# RS14100 register map
File version: 1.0
CPU: CM4 r0p1, little endian, MPU, FPU, 4 interrupt priority bits
Registers are 32-bit, read-write, reset 0x0 unless marked. A register's access mark holds for its fields unless they carry their own. Offsets are from the block's base; [hi:lo] are bit positions.

## CCI — CCI module helps external memories and peripherals to communicate with internal AHB bus with less number of pins
Base 0x46170000
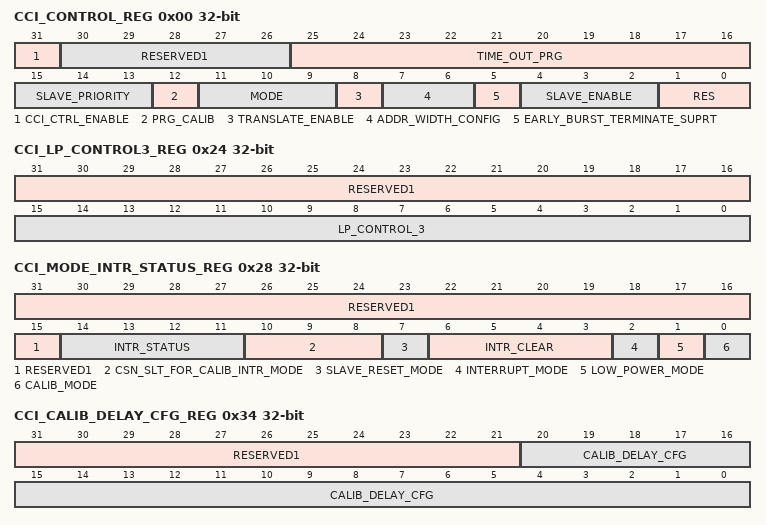
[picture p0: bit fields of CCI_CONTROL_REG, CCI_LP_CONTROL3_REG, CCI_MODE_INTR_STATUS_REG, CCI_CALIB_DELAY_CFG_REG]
0x00 CCI_CONTROL_REG — Direct Access Registers
  [31] CCI_CTRL_ENABLE — configurable time out value for slave response.
  [30:26] RESERVED1 — reser
  [25:16] TIME_OUT_PRG — configurable time out value for slave response.
  [15:13] SLAVE_PRIORITY — This bits will represents priority of the slaves
  [12] PRG_CALIB — By setting this bit, calibration turn around delay value will be configured
  [11:9] MODE — This bit represents mode of the interface
  [8] TRANSLATE_ENABLE — translation enable
  [7:6] ADDR_WIDTH_CONFIG — address width configuration of slave
  [5] EARLY_BURST_TERMINATE_SUPRT — Support for Early Burst Termination
  [4:2] SLAVE_ENABLE — Indicates Slaves enable
  [1:0] RES — reseR
0x04 CCI_LSB_A_S1_REG — Lower Address of slave 0 supported
0x08 CCI_LSB_A_S2_REG — LOWER Address of slave 0 supported
0x0C CCI_LSB_A_S3_REG — Lower Address of slave 0 supported
0x10 CCI_MSB_A_S1_REG — upper Address of slave 0 supported
0x14 CCI_MSB_A_S2_REG — UPPER Address of slave 0 supported
0x18 CCI_MSB_A_S3_REG — upper Address of slave 0 supported
0x1C CCI_LP_CONTROL1_REG — low power control - 1Configuration.It holds the lower 32 bits low power control values of the peer chip, once low power mode triggered then this bits will be transferred on to the interface
0x20 CCI_LP_CONTROL2_REG — low power control - 2 Configuration.It holds 64 to 33 bits the low power control values of the peer chip, once low power mode triggered then this bits will be transferred on to the interface
0x24 CCI_LP_CONTROL3_REG — low power control - 3 Configuration.It holds 80 to 64 bits the low power control values of the peer chip, once low power mode triggered then this bits will be transferred on to the interface
  [31:16] RESERVED1 — RESERV
  [15:0] LP_CONTROL_3 — It holds 80 to 64 bits the low power control values of the peer chip, once low power mode triggered then this bits will be transferred on to the interface
0x28 CCI_MODE_INTR_STATUS_REG — Interrupt Status
  [31:15] RESERVED1 — RESER
  [14:11] INTR_STATUS — These bits will represents the status of the interrupt in read mode
  [10:8] CSN_SLT_FOR_CALIB_INTR_MODE — CSN select value from register in calibration, and low power mode.
  [7] SLAVE_RESET_MODE — initiate the slave reset command from AMS
  [6:3] INTR_CLEAR — By setting this bits will clear the interrupt status
  [2] INTERRUPT_MODE — This bit is used to trigger the interrupt message mode
  [1] LOW_POWER_MODE — This bit is used to trigger the low power mode
  [0] CALIB_MODE — This bit is used to trigger the calibration mode
0x34 CCI_CALIB_DELAY_CFG_REG — Calibration delay Configuration
  [31:21] RESERVED1 — RESER
  [20:0] CALIB_DELAY_CFG — This register holds the turn around delays for the three ms chips
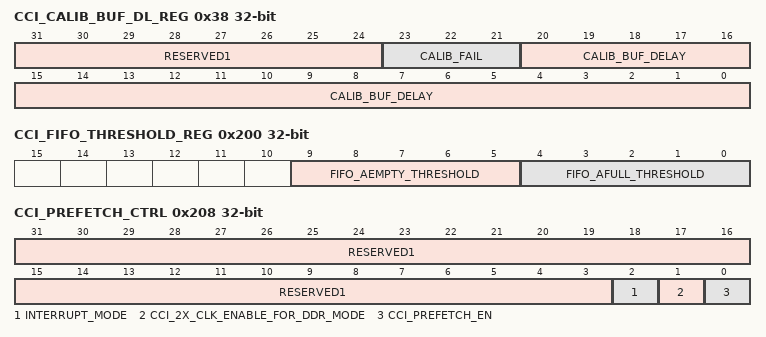
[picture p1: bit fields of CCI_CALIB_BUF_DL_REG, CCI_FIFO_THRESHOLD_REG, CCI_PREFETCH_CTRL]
0x38 CCI_CALIB_BUF_DL_REG — Calibration Maximum delay
  [31:24] RESERVED1 — RESER
  [23:21] CALIB_FAIL ro — this bits will represents the status of the calibration
  [20:0] CALIB_BUF_DELAY — This register holds the maximum tuning delays for the three ms chips
0x3C LP_CONTROL_4 — low power control
  [31:0] LP_CONTROL_4_ — It holds the lower 32 bits low power control values of the peer chip, once low power mode triggered then this bits will be transferred on to the interface
0x40 LP_CONTROL_5 — low power control
  [31:0] LP_CONTROL_5 — It holds the lower 32 bits low power control values of the peer chip, once low power mode triggered then this bits will be transferred on to the interfaces
0x200 CCI_FIFO_THRESHOLD_REG — CCI fifo threshold
  [9:5] FIFO_AEMPTY_THRESHOLD — ALMOST empty threshold
  [4:0] FIFO_AFULL_THRESHOLD — ALMOST full threshold
0x204 CCI_TRANS_ADDRESS
0x208 CCI_PREFETCH_CTRL — CCI prefetch control register
  [31:3] RESERVED1 — RESERV
  [2] INTERRUPT_MODE — This bit is used to trigger the interrupt message mode.
  [1] CCI_2X_CLK_ENABLE_FOR_DDR_MODE — It is an enable for CCI 2x clock in DDR mode
  [0] CCI_PREFETCH_EN — cci pre-fetch enables on AHB read operation.
